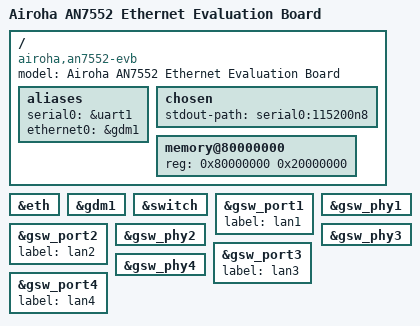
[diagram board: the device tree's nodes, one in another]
// SPDX-License-Identifier: (GPL-2.0-only OR BSD-2-Clause)
/dts-v1/;

/memreserve/ 0x80000000 0x200000;

#include "an7552.dtsi"

/ {
	model = "Airoha AN7552 Ethernet Evaluation Board";
	compatible = "airoha,an7552-evb", "airoha,an7552";

	aliases {
		serial0 = &uart1;
		ethernet0 = &gdm1;
	};

	chosen {
		stdout-path = "serial0:115200n8";
	};

	memory@80000000 {
		device_type = "memory";
		reg = <0x80000000 0x20000000>;
	};
};

&eth {
	status = "okay";
};

&gdm1 {
	status = "okay";
};

&switch {
	status = "okay";
};

&gsw_port1 {
	label = "lan1";
	status = "okay";
};

&gsw_phy1 {
	status = "okay";
};

&gsw_port2 {
	label = "lan2";
	status = "okay";
};

&gsw_phy2 {
	status = "okay";
};

&gsw_port3 {
	label = "lan3";
	status = "okay";
};

&gsw_phy3 {
	status = "okay";
};

&gsw_port4 {
	label = "lan4";
	status = "okay";
};

&gsw_phy4 {
	status = "okay";
};
